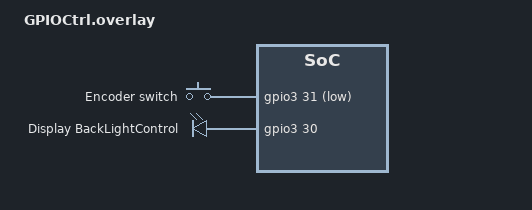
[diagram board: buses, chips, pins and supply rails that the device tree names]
#include <zephyr/dt-bindings/gpio/nxp-kinetis-gpio.h>
#include <zephyr/dt-bindings/input/input-event-codes.h>

/ {
	input_pins {
		compatible = "gpio-keys";
		debounce-interval-ms = <30>;

		eqdc_sw_pin: eqdc_sw_pin {
			gpios = <&gpio3 31 (GPIO_ACTIVE_LOW | GPIO_PULL_UP)>;
            zephyr,code = <INPUT_KEY_0>;
            label = "Encoder switch";
		};
	};

	output_pins {
		compatible = "gpio-leds";

		lvgl_bk_light_en: lvgl_bk_light_en{
			gpios = <&gpio3 30 (GPIO_ACTIVE_HIGH | GPIO_PULL_DOWN)>;
			label = "Display BackLightControl";
		};
	};

	aliases {
		enc-sw = &eqdc_sw_pin;
		lvgl-bk-en = &lvgl_bk_light_en;
	};
};
